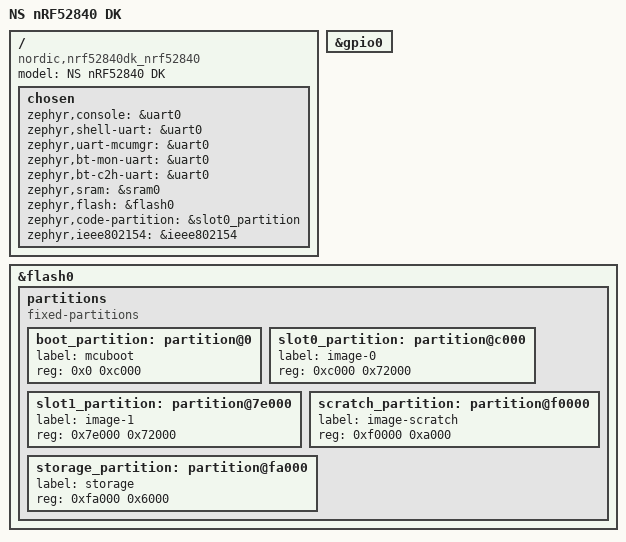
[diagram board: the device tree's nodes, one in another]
//
// gp-nrf-ble-blinky
// Copyright (c) 2023, Greg PFISTER. MIT Licennse
//
// THE SOFTWARE IS PROVIDED "AS IS", WITHOUT WARRANTY OF ANY KIND, EXPRESS OR
// IMPLIED, INCLUDING BUT NOT LIMITED TO THE WARRANTIES OF MERCHANTABILITY,
// FITNESS FOR A PARTICULAR PURPOSE AND NONINFRINGEMENT.IN NO EVENT SHALL THE
// AUTHORS OR COPYRIGHT HOLDERS BE LIABLE FOR ANY CLAIM, DAMAGES OR OTHER
// LIABILITY, WHETHER IN AN ACTION OF CONTRACT, TORT OR OTHERWISE, ARISING FROM,
// OUT OF OR IN CONNECTION WITH THE SOFTWARE OR THE USE OR OTHER DEALINGS IN THE
// SOFTWARE.
//

/dts-v1/;
#include <nordic/nrf52840_qiaa.dtsi>
#include "ns_nrf52840_dk-leds.dtsi"

/ {
	model = "NS nRF52840 DK";
	compatible = "nordic,nrf52840dk_nrf52840";

	chosen {
		zephyr,console = &uart0;
		zephyr,shell-uart = &uart0;
		zephyr,uart-mcumgr = &uart0;
		zephyr,bt-mon-uart = &uart0;
		zephyr,bt-c2h-uart = &uart0;
		zephyr,sram = &sram0;
		zephyr,flash = &flash0;
		zephyr,code-partition = &slot0_partition;
		zephyr,ieee802154 = &ieee802154;
	};
};

&gpio0 {
	status = "okay";
};


&flash0 {
	partitions {
		compatible = "fixed-partitions";
		#address-cells = <1>;
		#size-cells = <1>;

		boot_partition: partition@0 {
			label = "mcuboot";
			reg = <0x0 0xc000>;
		};
		slot0_partition: partition@c000 {
			label = "image-0";
			reg = <0xc000 0x72000>;
		};
		slot1_partition: partition@7e000 {
			label = "image-1";
			reg = <0x7e000 0x72000>;
		};
		scratch_partition: partition@f0000 {
			label = "image-scratch";
			reg = <0xf0000 0xa000>;
		};
		storage_partition: partition@fa000 {
			label = "storage";
			reg = <0xfa000 0x6000>;
		};
	};
};

